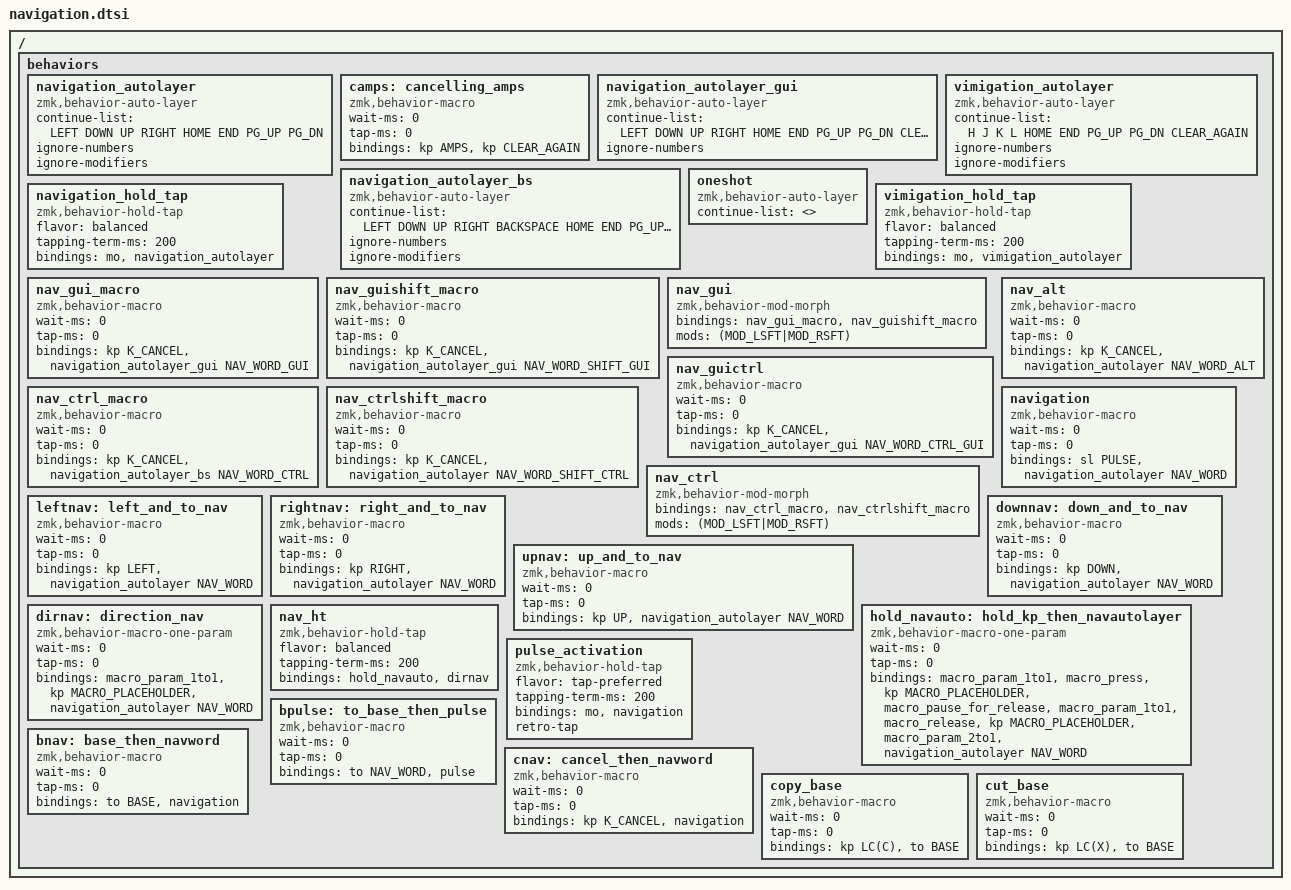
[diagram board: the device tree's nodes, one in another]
/ {
	behaviors {

		navigation_autolayer: navigation_autolayer {
			compatible = "zmk,behavior-auto-layer";
			#binding-cells = <1>;
			continue-list = <LEFT DOWN UP RIGHT HOME END PG_UP PG_DN /* villt alls ekki CLEAR_AGAIN hér því notar það í amps */
                       >;
			ignore-numbers;
			ignore-modifiers;
		};

    /* þetta var gert til að laga bug sem lét amps virka illa með nav autolayernum */
		camps: cancelling_amps {
			compatible = "zmk,behavior-macro";
			#binding-cells = <0>;
			wait-ms = <0>;
			tap-ms = <0>;
			bindings = <&kp AMPS>, <&kp CLEAR_AGAIN>;
		};

		navigation_autolayer_gui: navigation_autolayer_gui {
			compatible = "zmk,behavior-auto-layer";
			#binding-cells = <1>;
			continue-list = <LEFT DOWN UP RIGHT HOME END PG_UP PG_DN CLEAR_AGAIN
                       LSHIFT RSHIFT LCTRL RCTRL LALT RALT>;
			ignore-numbers;
			/* ignore-modifiers; */
		};

		navigation_autolayer_bs: navigation_autolayer_bs {
			compatible = "zmk,behavior-auto-layer";
			#binding-cells = <1>;
			continue-list = <LEFT DOWN UP RIGHT BACKSPACE HOME END PG_UP PG_DN CLEAR_AGAIN>;
			ignore-numbers;
			ignore-modifiers;
		};

		vimigation_autolayer: vimigation_autolayer {
			compatible = "zmk,behavior-auto-layer";
			#binding-cells = <1>;
			continue-list = <H J K L HOME END PG_UP PG_DN CLEAR_AGAIN>;
			ignore-numbers;
			ignore-modifiers;
		};

		oneshot: oneshot {
			compatible = "zmk,behavior-auto-layer";
			#binding-cells = <1>;
			continue-list = <>;
		};

		/* navigation_with_overlay: navigation_with_overlay { */
		/* 	compatible = "zmk,behavior-macro"; */
		/* 	#binding-cells = <0>; */
		/* 	bindings = < */
		/* 	&navigation_autolayer NAV_WORD */
		/* 	&navigation_autolayer KCAN_OVER */
		/* 	>; */
		/* }; */
		
		/* navigation_mod_morph: navigation_mod_morph { */
		/*     compatible = "zmk,behavior-mod-morph"; */
		/*     #binding-cells = <0>; */
		/*     bindings = <&navigation_with_overlay>, <&to NAVIGATION>; */
		/*     mods = <(MOD_LSFT|MOD_RSFT)>; */
		/* }; */

		navigation_hold_tap: navigation_hold_tap {
		  compatible = "zmk,behavior-hold-tap";
		  #binding-cells = <2>;
		  flavor = "balanced";
		  tapping-term-ms = <200>;
		  bindings = <&mo>, <&navigation_autolayer>;
		};

		vimigation_hold_tap: vimigation_hold_tap {
		  compatible = "zmk,behavior-hold-tap";
		  #binding-cells = <2>;
		  flavor = "balanced";
		  tapping-term-ms = <200>;
		  bindings = <&mo>, <&vimigation_autolayer>;
		};


    #define navigation_base navigation_hold_tap NAV_WORD NAV_WORD
    #define nav_mirrored navigation_autolayer NAV_WORD_MIRRORED
    #define vim vimigation_hold_tap VIM_WORD VIM_WORD
    #define pag navigation_hold_tap PAGE_WORD PAGE_WORD


    /* #define nav_gui navigation_autolayer_gui NAV_WORD_GUI */
    /* #define nav_ctrl navigation_autolayer_bs NAV_WORD_CTRL */
    /* #define nav_alt navigation_autolayer NAV_WORD_ALT */
    /* #define nav_shift navigation_autolayer NAV_WORD_SHIFT */
		nav_gui_macro: nav_gui_macro {
			compatible = "zmk,behavior-macro";
			#binding-cells = <0>;
			wait-ms = <0>;
			tap-ms = <0>;
			bindings = <&kp K_CANCEL>, <&navigation_autolayer_gui NAV_WORD_GUI>;
		};

		nav_guishift_macro: nav_guishift_macro {
			compatible = "zmk,behavior-macro";
			#binding-cells = <0>;
			wait-ms = <0>;
			tap-ms = <0>;
			bindings = <&kp K_CANCEL>, <&navigation_autolayer_gui NAV_WORD_SHIFT_GUI>;
		};

		nav_gui: nav_gui {
			compatible = "zmk,behavior-mod-morph";
			#binding-cells = <0>;
			bindings = <&nav_gui_macro>, <&nav_guishift_macro>;
			mods = <(MOD_LSFT|MOD_RSFT)>;
		};

		nav_guictrl: nav_guictrl {
			compatible = "zmk,behavior-macro";
			#binding-cells = <0>;
			wait-ms = <0>;
			tap-ms = <0>;
			bindings = <&kp K_CANCEL>, <&navigation_autolayer_gui NAV_WORD_CTRL_GUI >;
		};

		nav_ctrl_macro: nav_ctrl_macro {
			compatible = "zmk,behavior-macro";
			#binding-cells = <0>;
			wait-ms = <0>;
			tap-ms = <0>;
			bindings = <&kp K_CANCEL>, <&navigation_autolayer_bs NAV_WORD_CTRL>;
		};

		nav_ctrlshift_macro: nav_ctrlshift_macro {
			compatible = "zmk,behavior-macro";
			#binding-cells = <0>;
			wait-ms = <0>;
			tap-ms = <0>;
			bindings = <&kp K_CANCEL>, <&navigation_autolayer NAV_WORD_SHIFT_CTRL>;
		};

		nav_ctrl: nav_ctrl {
			compatible = "zmk,behavior-mod-morph";
			#binding-cells = <0>;
			bindings = <&nav_ctrl_macro>, <&nav_ctrlshift_macro>;
			mods = <(MOD_LSFT|MOD_RSFT)>;
		};

		nav_alt: nav_alt {
			compatible = "zmk,behavior-macro";
			#binding-cells = <0>;
			wait-ms = <0>;
			tap-ms = <0>;
			bindings = <&kp K_CANCEL>, <&navigation_autolayer NAV_WORD_ALT>;
		};

		navigation: navigation {
			compatible = "zmk,behavior-macro";
			#binding-cells = <0>;
			wait-ms = <0>;
			tap-ms = <0>;
			bindings = <&sl PULSE>, <&navigation_autolayer NAV_WORD>;
		};

		leftnav: left_and_to_nav {
			compatible = "zmk,behavior-macro";
			#binding-cells = <0>;
			wait-ms = <0>;
			tap-ms = <0>;
			bindings = <&kp LEFT>, <&navigation_autolayer NAV_WORD>;
		};

		rightnav: right_and_to_nav {
			compatible = "zmk,behavior-macro";
			#binding-cells = <0>;
			wait-ms = <0>;
			tap-ms = <0>;
			bindings = <&kp RIGHT>, <&navigation_autolayer NAV_WORD>;
		};

		upnav: up_and_to_nav {
			compatible = "zmk,behavior-macro";
			#binding-cells = <0>;
			wait-ms = <0>;
			tap-ms = <0>;
			bindings = <&kp UP>, <&navigation_autolayer NAV_WORD>;
		};

		downnav: down_and_to_nav {
			compatible = "zmk,behavior-macro";
			#binding-cells = <0>;
			wait-ms = <0>;
			tap-ms = <0>;
			bindings = <&kp DOWN>, <&navigation_autolayer NAV_WORD>;
		};

		dirnav: direction_nav {
        compatible = "zmk,behavior-macro-one-param";
        wait-ms = <0>;
        tap-ms = <0>;
        #binding-cells = <1>;
			  bindings = <&macro_param_1to1>, <&kp MACRO_PLACEHOLDER>, <&navigation_autolayer NAV_WORD>;
		};


    hold_navauto: hold_kp_then_navautolayer {
        compatible = "zmk,behavior-macro-one-param";
        wait-ms = <0>;
        tap-ms = <0>;
        #binding-cells = <1>;
        bindings
            = 
            <&macro_param_1to1>
            , <&macro_press &kp MACRO_PLACEHOLDER>
            , <&macro_pause_for_release>
            , <&macro_param_1to1>
            , <&macro_release &kp MACRO_PLACEHOLDER>
            , <&macro_param_2to1>
            , <&navigation_autolayer NAV_WORD>
            ;
    };

		nav_ht: nav_ht {
		  compatible = "zmk,behavior-hold-tap";
		  #binding-cells = <2>;
		  flavor = "balanced";
		  tapping-term-ms = <200>;
		  bindings = <&hold_navauto>, <&dirnav>;
		};

    #define leftnav nav_ht LEFT LEFT
    #define downnav nav_ht DOWN DOWN
    #define upnav nav_ht UP UP
    #define rightnav nav_ht RIGHT RIGHT

    /* #define leftnav hold_navauto LEFT NAV_WORD */
    /* #define downnav hold_navauto DOWN NAV_WORD */
    /* #define upnav hold_navauto UP NAV_WORD */
    /* #define rightnav hold_navauto RIGHT NAV_WORD */


		pulse_activation: pulse_activation {
		  compatible = "zmk,behavior-hold-tap";
		  #binding-cells = <2>;
      flavor = "tap-preferred";
		  tapping-term-ms = <200>;
		  bindings = <&mo>, <&navigation>;
      retro-tap;
		};

    #define pulse pulse_activation PULSE 0

		bpulse: to_base_then_pulse {
			compatible = "zmk,behavior-macro";
			#binding-cells = <0>;
			wait-ms = <0>;
			tap-ms = <0>;
			bindings = <&to NAV_WORD>, <&pulse>;
      /* hugmyndin er augljóslega ekki að fara á nav word, þarf bara að brjóta tristate */
		};

		cnav: cancel_then_navword {
			compatible = "zmk,behavior-macro";
			#binding-cells = <0>;
			wait-ms = <0>;
			tap-ms = <0>;
			bindings = <&kp K_CANCEL>, <&navigation>;
		};

		bnav: base_then_navword {
			compatible = "zmk,behavior-macro";
			#binding-cells = <0>;
			wait-ms = <0>;
			tap-ms = <0>;
			bindings = <&to BASE>, <&navigation>;
		};


		copy_base: copy_base {
			compatible = "zmk,behavior-macro";
			#binding-cells = <0>;
			wait-ms = <0>;
			tap-ms = <0>;
			bindings = <&kp LC(C)>, <&to BASE>;
		};


		cut_base: cut_base {
			compatible = "zmk,behavior-macro";
			#binding-cells = <0>;
			wait-ms = <0>;
			tap-ms = <0>;
			bindings = <&kp LC(X)>, <&to BASE>;
		};

		/* navigation: navigation { */
		/* 	compatible = "zmk,behavior-mod-morph"; */
		/* 	#binding-cells = <0>; */
		/* 	bindings = <&navigation_hold_tap NAV_WORD NAV_WORD>, <&vimigation_hold_tap VIM_WORD VIM_WORD>; */
		/* 	mods = <(MOD_LSFT|MOD_RSFT)>; */
		/* 	keep-mods = <(MOD_LSFT)>; */
		/* }; */

	};
};
